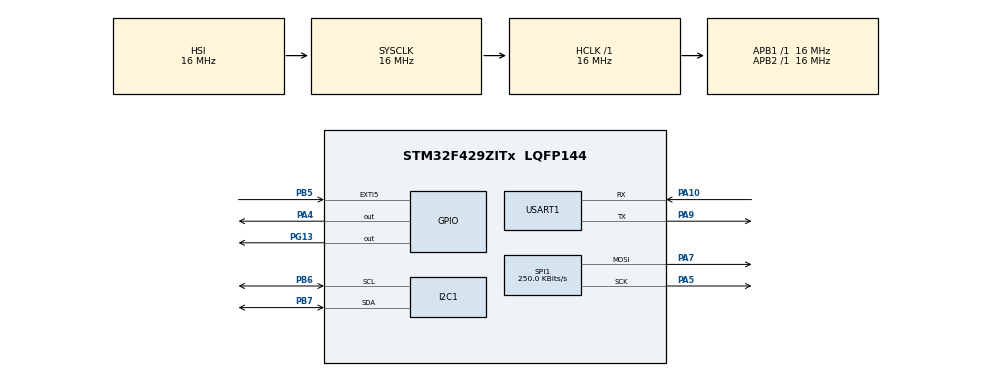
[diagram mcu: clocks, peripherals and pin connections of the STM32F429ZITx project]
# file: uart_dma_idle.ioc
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Dma.Request0=USART1_RX
Dma.Request1=USART1_TX
Dma.USART1_RX.0.Direction=DMA_PERIPH_TO_MEMORY
Dma.USART1_RX.0.FIFOMode=DMA_FIFOMODE_DISABLE
Dma.USART1_RX.0.Instance=DMA2_Stream2
Dma.USART1_RX.0.MemDataAlignment=DMA_MDATAALIGN_BYTE
Dma.USART1_RX.0.MemInc=DMA_MINC_ENABLE
Dma.USART1_RX.0.Mode=DMA_CIRCULAR
Dma.USART1_RX.0.PeriphDataAlignment=DMA_PDATAALIGN_BYTE
Dma.USART1_RX.0.PeriphInc=DMA_PINC_DISABLE
Dma.USART1_RX.0.Priority=DMA_PRIORITY_LOW
Dma.USART1_TX.1.Direction=DMA_MEMORY_TO_PERIPH
Dma.USART1_TX.1.FIFOMode=DMA_FIFOMODE_DISABLE
Dma.USART1_TX.1.Instance=DMA2_Stream7
Dma.USART1_TX.1.MemDataAlignment=DMA_MDATAALIGN_BYTE
Dma.USART1_TX.1.MemInc=DMA_MINC_ENABLE
Dma.USART1_TX.1.Mode=DMA_NORMAL
Dma.USART1_TX.1.PeriphDataAlignment=DMA_PDATAALIGN_BYTE
Dma.USART1_TX.1.PeriphInc=DMA_PINC_DISABLE
Dma.USART1_TX.1.Priority=DMA_PRIORITY_LOW
Mcu.Family=STM32F4
Mcu.Name=STM32F429ZITx
Mcu.Package=LQFP144
NVIC.DMA2_Stream2_IRQn=true\:0\:0\:false\:false\:true\:false\:true\:true
NVIC.DMA2_Stream7_IRQn=true\:0\:0\:false\:false\:true\:false\:true\:true
NVIC.EXTI9_5_IRQn=true\:0\:0\:false\:false\:true\:true\:true\:true
NVIC.PriorityGroup=NVIC_PRIORITYGROUP_4
NVIC.USART1_IRQn=true\:0\:0\:false\:false\:true\:true\:true\:true
PA10.Mode=Asynchronous
PA10.Signal=USART1_RX
PA4.GPIO_PuPd=GPIO_PULLUP
PA4.Signal=GPIO_Output
PA5.Mode=TX_Only_Simplex_Unidirect_Master
PA5.Signal=SPI1_SCK
PA7.GPIO_PuPd=GPIO_NOPULL
PA7.Mode=TX_Only_Simplex_Unidirect_Master
PA7.Signal=SPI1_MOSI
PA9.Mode=Asynchronous
PA9.Signal=USART1_TX
PB5.GPIO_ModeDefaultEXTI=GPIO_MODE_IT_FALLING
PB5.GPIO_PuPd=GPIO_PULLUP
PB5.Signal=GPXTI5
PB6.Mode=I2C
PB6.Signal=I2C1_SCL
PB7.Mode=I2C
PB7.Signal=I2C1_SDA
PG13.Signal=GPIO_Output
ProjectManager.HeapSize=0x200
ProjectManager.StackSize=0x400
ProjectManager.TargetToolchain=STM32CubeIDE
RCC.AHBFreq_Value=16000000
RCC.APB1Freq_Value=16000000
RCC.APB2Freq_Value=16000000
RCC.CortexFreq_Value=16000000
RCC.HSE_VALUE=25000000
RCC.HSI_VALUE=16000000
RCC.LSE_VALUE=32768
RCC.SYSCLKFreq_VALUE=16000000
RCC.VCOOutputFreq_Value=192000000
SPI1.BaudRatePrescaler=SPI_BAUDRATEPRESCALER_64
SPI1.CLKPhase=SPI_PHASE_1EDGE
SPI1.CLKPolarity=SPI_POLARITY_HIGH
SPI1.CalculateBaudRate=250.0 KBits/s
SPI1.DataSize=SPI_DATASIZE_16BIT
SPI1.Direction=SPI_DIRECTION_2LINES
SPI1.Mode=SPI_MODE_MASTER
SPI1.VirtualType=VM_MASTER
USART1.VirtualMode=VM_ASYNC
board=custom

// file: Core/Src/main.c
/* USER CODE BEGIN Header */
/**
  ******************************************************************************
  * @file           : main.c
  * @brief          : Main program body
  ******************************************************************************
  * @attention
  *
  * Copyright (c) 2022 STMicroelectronics.
  * All rights reserved.
  *
  * This software is licensed under terms that can be found in the LICENSE file
  * in the root directory of this software component.
  * If no LICENSE file comes with this software, it is provided AS-IS.
  *
  ******************************************************************************
  */
/* USER CODE END Header */
#include "main.h"

/* USER CODE BEGIN Includes */
#include <string.h>
#include <stdio.h>
#include <stdbool.h>
/* USER CODE END Includes */

/* USER CODE BEGIN PM */
#define RXBUF_MAX 10
/* USER CODE END PM */

I2C_HandleTypeDef hi2c1;

SPI_HandleTypeDef hspi1;

UART_HandleTypeDef huart1;
DMA_HandleTypeDef hdma_usart1_rx;
DMA_HandleTypeDef hdma_usart1_tx;

/* USER CODE BEGIN PV */
uint8_t UartRxDMA_buf[RXBUF_MAX];
uint32_t UartRxDMANum = 0;
bool bUartTxDMACpltFlg = true,bUartDataUpdateFlg = false;
/* USER CODE END PV */

void SystemClock_Config(void);
static void MX_GPIO_Init(void);
static void MX_DMA_Init(void);
static void MX_I2C1_Init(void);
static void MX_USART1_UART_Init(void);
static void MX_SPI1_Init(void);

int main(void)
{

  /* MCU Configuration--------------------------------------------------------*/

  /* Reset of all peripherals, Initializes the Flash interface and the Systick. */
  HAL_Init();

  /* Configure the system clock */
  SystemClock_Config();

  /* Initialize all configured peripherals */
  MX_GPIO_Init();
  MX_DMA_Init();
  MX_I2C1_Init();
  MX_USART1_UART_Init();
  MX_SPI1_Init();
  /* USER CODE BEGIN 2 */

  SET_BIT(huart1.Instance->CR3,USART_CR3_DMAT);
  SET_BIT(huart1.Instance->CR3,USART_CR3_DMAR);
  __HAL_UART_ENABLE_IT(&huart1,UART_IT_IDLE);
  HAL_UART_Receive_DMA(&huart1, UartRxDMA_buf, RXBUF_MAX);
  /* USER CODE END 2 */

  /* Infinite loop */
  while (1)
  {

  }
}

void SystemClock_Config(void)
{
  RCC_OscInitTypeDef RCC_OscInitStruct = {0};
  RCC_ClkInitTypeDef RCC_ClkInitStruct = {0};

  /** Configure the main internal regulator output voltage
  */
  __HAL_RCC_PWR_CLK_ENABLE();
  __HAL_PWR_VOLTAGESCALING_CONFIG(PWR_REGULATOR_VOLTAGE_SCALE3);

  /** Initializes the RCC Oscillators according to the specified parameters
  * in the RCC_OscInitTypeDef structure.
  */
  RCC_OscInitStruct.OscillatorType = RCC_OSCILLATORTYPE_HSI;
  RCC_OscInitStruct.HSIState = RCC_HSI_ON;
  RCC_OscInitStruct.HSICalibrationValue = RCC_HSICALIBRATION_DEFAULT;
  RCC_OscInitStruct.PLL.PLLState = RCC_PLL_NONE;
  if (HAL_RCC_OscConfig(&RCC_OscInitStruct) != HAL_OK)
  {
    Error_Handler();
  }

  /** Initializes the CPU, AHB and APB buses clocks
  */
  RCC_ClkInitStruct.ClockType = RCC_CLOCKTYPE_HCLK|RCC_CLOCKTYPE_SYSCLK
                              |RCC_CLOCKTYPE_PCLK1|RCC_CLOCKTYPE_PCLK2;
  RCC_ClkInitStruct.SYSCLKSource = RCC_SYSCLKSOURCE_HSI;
  RCC_ClkInitStruct.AHBCLKDivider = RCC_SYSCLK_DIV1;
  RCC_ClkInitStruct.APB1CLKDivider = RCC_HCLK_DIV1;
  RCC_ClkInitStruct.APB2CLKDivider = RCC_HCLK_DIV1;

  if (HAL_RCC_ClockConfig(&RCC_ClkInitStruct, FLASH_LATENCY_0) != HAL_OK)
  {
    Error_Handler();
  }
}

static void MX_I2C1_Init(void)
{

  hi2c1.Instance = I2C1;
  hi2c1.Init.ClockSpeed = 100000;
  hi2c1.Init.DutyCycle = I2C_DUTYCYCLE_2;
  hi2c1.Init.OwnAddress1 = 0;
  hi2c1.Init.AddressingMode = I2C_ADDRESSINGMODE_7BIT;
  hi2c1.Init.DualAddressMode = I2C_DUALADDRESS_DISABLE;
  hi2c1.Init.OwnAddress2 = 0;
  hi2c1.Init.GeneralCallMode = I2C_GENERALCALL_DISABLE;
  hi2c1.Init.NoStretchMode = I2C_NOSTRETCH_DISABLE;
  if (HAL_I2C_Init(&hi2c1) != HAL_OK)
  {
    Error_Handler();
  }

  /** Configure Analogue filter
  */
  if (HAL_I2CEx_ConfigAnalogFilter(&hi2c1, I2C_ANALOGFILTER_ENABLE) != HAL_OK)
  {
    Error_Handler();
  }

  /** Configure Digital filter
  */
  if (HAL_I2CEx_ConfigDigitalFilter(&hi2c1, 0) != HAL_OK)
  {
    Error_Handler();
  }

}

static void MX_SPI1_Init(void)
{

  /* SPI1 parameter configuration*/
  hspi1.Instance = SPI1;
  hspi1.Init.Mode = SPI_MODE_MASTER;
  hspi1.Init.Direction = SPI_DIRECTION_2LINES;
  hspi1.Init.DataSize = SPI_DATASIZE_16BIT;
  hspi1.Init.CLKPolarity = SPI_POLARITY_HIGH;
  hspi1.Init.CLKPhase = SPI_PHASE_1EDGE;
  hspi1.Init.NSS = SPI_NSS_SOFT;
  hspi1.Init.BaudRatePrescaler = SPI_BAUDRATEPRESCALER_64;
  hspi1.Init.FirstBit = SPI_FIRSTBIT_MSB;
  hspi1.Init.TIMode = SPI_TIMODE_DISABLE;
  hspi1.Init.CRCCalculation = SPI_CRCCALCULATION_DISABLE;
  hspi1.Init.CRCPolynomial = 10;
  if (HAL_SPI_Init(&hspi1) != HAL_OK)
  {
    Error_Handler();
  }

}

static void MX_USART1_UART_Init(void)
{

  huart1.Instance = USART1;
  huart1.Init.BaudRate = 115200;
  huart1.Init.WordLength = UART_WORDLENGTH_8B;
  huart1.Init.StopBits = UART_STOPBITS_1;
  huart1.Init.Parity = UART_PARITY_NONE;
  huart1.Init.Mode = UART_MODE_TX_RX;
  huart1.Init.HwFlowCtl = UART_HWCONTROL_NONE;
  huart1.Init.OverSampling = UART_OVERSAMPLING_16;
  if (HAL_UART_Init(&huart1) != HAL_OK)
  {
    Error_Handler();
  }

}

static void MX_DMA_Init(void)
{

  /* DMA controller clock enable */
  __HAL_RCC_DMA2_CLK_ENABLE();

  /* DMA interrupt init */
  /* DMA2_Stream2_IRQn interrupt configuration */
  HAL_NVIC_SetPriority(DMA2_Stream2_IRQn, 0, 0);
  HAL_NVIC_EnableIRQ(DMA2_Stream2_IRQn);
  /* DMA2_Stream7_IRQn interrupt configuration */
  HAL_NVIC_SetPriority(DMA2_Stream7_IRQn, 0, 0);
  HAL_NVIC_EnableIRQ(DMA2_Stream7_IRQn);

}

static void MX_GPIO_Init(void)
{
  GPIO_InitTypeDef GPIO_InitStruct = {0};

  /* GPIO Ports Clock Enable */
  __HAL_RCC_GPIOA_CLK_ENABLE();
  __HAL_RCC_GPIOG_CLK_ENABLE();
  __HAL_RCC_GPIOB_CLK_ENABLE();

  /*Configure GPIO pin Output Level */
  HAL_GPIO_WritePin(GPIOA, GPIO_PIN_4, GPIO_PIN_RESET);

  /*Configure GPIO pin Output Level */
  HAL_GPIO_WritePin(GPIOG, GPIO_PIN_13, GPIO_PIN_RESET);

  /*Configure GPIO pin : PA4 */
  GPIO_InitStruct.Pin = GPIO_PIN_4;
  GPIO_InitStruct.Mode = GPIO_MODE_OUTPUT_PP;
  GPIO_InitStruct.Pull = GPIO_PULLUP;
  GPIO_InitStruct.Speed = GPIO_SPEED_FREQ_LOW;
  HAL_GPIO_Init(GPIOA, &GPIO_InitStruct);

  /*Configure GPIO pin : PG13 */
  GPIO_InitStruct.Pin = GPIO_PIN_13;
  GPIO_InitStruct.Mode = GPIO_MODE_OUTPUT_PP;
  GPIO_InitStruct.Pull = GPIO_NOPULL;
  GPIO_InitStruct.Speed = GPIO_SPEED_FREQ_LOW;
  HAL_GPIO_Init(GPIOG, &GPIO_InitStruct);

  /*Configure GPIO pin : PB5 */
  GPIO_InitStruct.Pin = GPIO_PIN_5;
  GPIO_InitStruct.Mode = GPIO_MODE_IT_FALLING;
  GPIO_InitStruct.Pull = GPIO_PULLUP;
  HAL_GPIO_Init(GPIOB, &GPIO_InitStruct);

  /* EXTI interrupt init*/
  HAL_NVIC_SetPriority(EXTI9_5_IRQn, 0, 0);
  HAL_NVIC_EnableIRQ(EXTI9_5_IRQn);

}

/* USER CODE BEGIN 4 */
void HAL_UART_RxCpltCallback(UART_HandleTypeDef *huart) {
	if (huart->Instance==USART1) {
		UartRxDMANum = RXBUF_MAX - huart->hdmarx->Instance->NDTR;  // UartRxDMA_Buf_pW is the number of received data.
	}
}
/* USER CODE END 4 */

void Error_Handler(void)
{
  __disable_irq();
  while (1)
  {
  }
}
